# MKL28T7_CORE0 register map
Vendor: Freescale Semiconductor, Inc.; Series: Kinetis_L; File version: 1.6
CPU: CM0PLUS r0p0, little endian, no MPU, no FPU, VTOR, 2 interrupt priority bits
Registers are 32-bit, read-write, reset 0x0 unless marked. A register's access mark holds for its fields unless they carry their own. Offsets are from the block's base; [hi:lo] are bit positions; {n}, {i} and the like mark numbered series; 'fields as' and 'values as' point back to an identical list.

## INTMUX0 — Interrupt Multiplexer
Base 0x40024000; register names take the prefix INTMUX0_
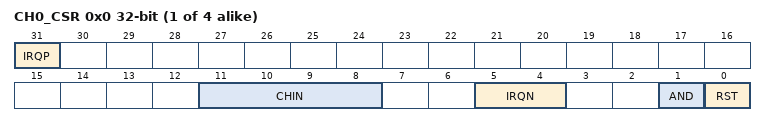
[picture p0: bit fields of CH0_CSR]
{0x0+0x40*i} CH{i}_CSR (i=0..3) — Channel n Control Status Register
  [31] IRQP ro — Channel Interrupt Request Pending
    0=No interrupt is pending; 1=The interrupt output of this channel is pending
  [11:8] CHIN ro — Channel Instance Number
  [5:4] IRQN ro — Channel Input Number
    0=32 interrupt inputs
  [1] AND — Logic AND
    0=Logic OR all enabled interrupt inputs; 1=Logic AND all enabled interrupt inputs
  [0] RST — Software Reset
    0=No operation; 1=Perform a software reset on this channel
{0x4+0x40*i} CH{i}_VEC (i=0..3) ro — Channel n Vector Number Register
  [13:2] VECN — Vector Number
{0x10+0x40*i} CH{i}_IER_31_0 (i=0..3) — Channel n Interrupt Enable Register
  [31:0] INTE — Interrupt Enable
    0=Interrupt is disabled; 1=Interrupt is enabled
{0x20+0x40*i} CH{i}_IPR_31_0 (i=0..3) ro — Channel n Interrupt Pending Register
  [31:0] INTP — Interrupt Pending
    0=No interrupt; 1=Interrupt is pending

## TRGMUX0
Base 0x40027000
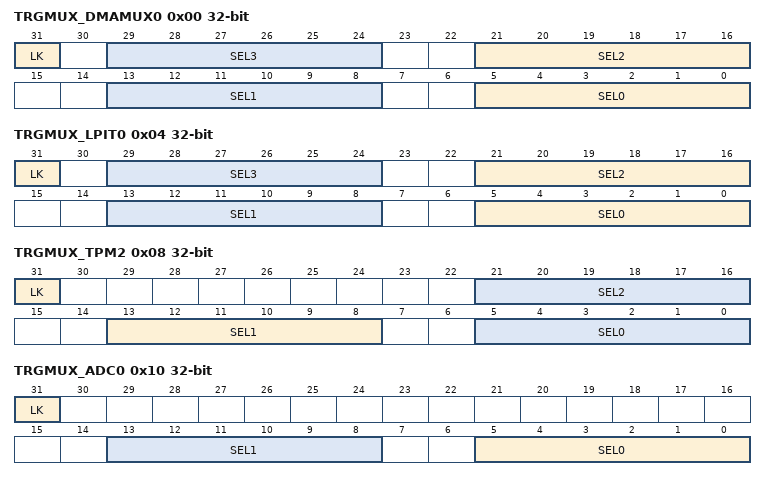
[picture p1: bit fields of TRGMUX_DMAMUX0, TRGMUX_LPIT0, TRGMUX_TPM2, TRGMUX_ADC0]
0x00 TRGMUX_DMAMUX0 — TRGMUX TRGCFG Register
  [31] LK — Enable
    0=Register can be written; 1=Register cannot be written until the next system Reset
  [29:24] SEL3 — Trigger MUX Input 3 Source Select
    0=Trigger function is disabled; 1=Port pin trigger input is selected; {v}=FlexIO Timer {v-2} input is selected (v=2..9); 10=TPM0 Overflow is selected; 11=TPM0 Channel 0 is selected; 12=TPM0 Channel 1 is selected; 13=TPM1 Overflow is selected; 14=TPM1 Channel 0 is selected; 15=TPM1 Channel 1 is selected; {v}=LPIT1 Channel {v-16} is selected (v=16..19); 20=LPUART0 RX Data is selected; 21=LPUART0 TX Data is selected; 22=LPUART0 RX Idle is selected; 23=LPUART1 RX Data is selected; 24=LPUART1 TX Data is selected; 25=LPUART1 RX Idle is selected; 26=LPI2C0 Master STOP is selected; 27=LPI2C0 Slave STOP is selected; 28=LPI2C1 Master STOP is selected; 29=LPI2C1 Slave STOP is selected; 30=LPSPI0 Frame is selected; 31=LPSPI0 RX data is selected; 32=LPSPI1 Frame is selected; 33=LPSPI1 RX data is selected; 34=RTC Seconds Counter is selected; 35=RTC Alarm is selected; 36=LPTMR0 Trigger is selected; 37=LPTMR1 Trigger is selected; 38=CMP0 Output is selected; 39=CMP1 Output is selected; 40=ADC0 Conversion A Complete is selected; 41=ADC0 Conversion B Complete is selected; 42=Port A Pin Trigger is selected; 43=Port B Pin Trigger is selected; 44=Port C Pin Trigger is selected; 45=Port D Pin Trigger is selected; 46=Port E Pin Trigger is selected; 47=TPM2 Overflow selected; 48=TPM2 Channel 0 is selected; 49=TPM2 Channel 1 is selected; {v}=LPIT0 Channel {v-50} is selected (v=50..53); 54=USB Start-of-Frame is selected; 55=LPUART2 RX Data is selected; 56=LPUART2 TX Data is selected; 57=LPUART2 RX Idle is selected; 58=LPI2C2 Master STOP is selected; 59=LPI2C2 Slave STOP is selected; 60=LPSPI2 Frame is selected; 61=LPSPI2 RX Data is selected; 62=SAI TX Frame Sync selected; 63=SAI RX Frame Sync is selected
  [21:16] SEL2 — Trigger MUX Input 2 Source Select
  [13:8] SEL1 — Trigger MUX Input 1 Source Select
  [5:0] SEL0 — Trigger MUX Input 0 Source Select
0x04 TRGMUX_LPIT0 — TRGMUX TRGCFG Register
  fields as TRGMUX_DMAMUX0
0x08 TRGMUX_TPM2 — TRGMUX TRGCFG Register
  [31] LK — Enable
    values as TRGMUX_DMAMUX0.LK
  [21:16] SEL2 — Trigger MUX Input 2 Source Select
  [13:8] SEL1 — Trigger MUX Input 1 Source Select
  [5:0] SEL0 — Trigger MUX Input 0 Source Select
0x10 TRGMUX_ADC0 — TRGMUX TRGCFG Register
  [31] LK — Enable
    values as TRGMUX_DMAMUX0.LK
  [13:8] SEL1 — Trigger MUX Input 1 Source Select
  [5:0] SEL0 — Trigger MUX Input 0 Source Select
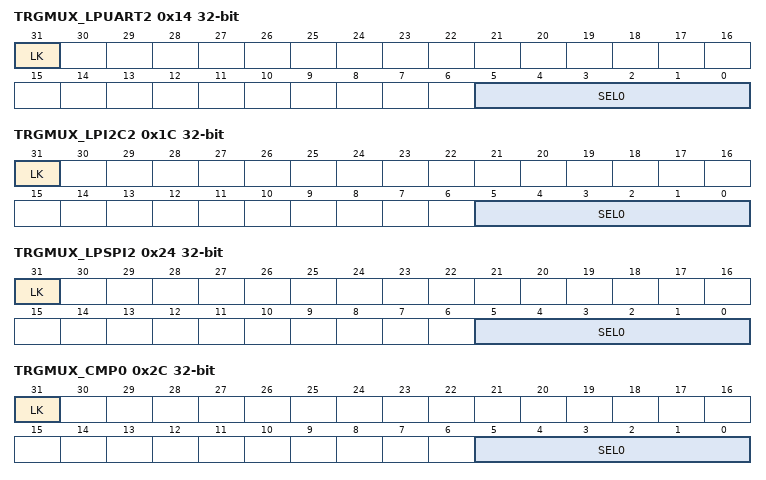
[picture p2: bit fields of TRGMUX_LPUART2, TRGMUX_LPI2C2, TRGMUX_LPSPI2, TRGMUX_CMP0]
0x14 TRGMUX_LPUART2 — TRGMUX TRGCFG Register
  [31] LK — Enable
    values as TRGMUX_DMAMUX0.LK
  [5:0] SEL0 — Trigger MUX Input 0 Source Select
0x1C TRGMUX_LPI2C2 — TRGMUX TRGCFG Register
  fields as TRGMUX_LPUART2
0x24 TRGMUX_LPSPI2 — TRGMUX TRGCFG Register
  fields as TRGMUX_LPUART2
0x2C TRGMUX_CMP0 — TRGMUX TRGCFG Register
  fields as TRGMUX_LPUART2
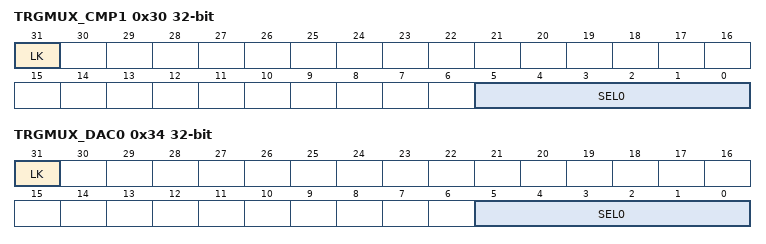
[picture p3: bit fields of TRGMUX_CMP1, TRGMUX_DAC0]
0x30 TRGMUX_CMP1 — TRGMUX TRGCFG Register
  fields as TRGMUX_LPUART2
0x34 TRGMUX_DAC0 — TRGMUX TRGCFG Register
  fields as TRGMUX_LPUART2
